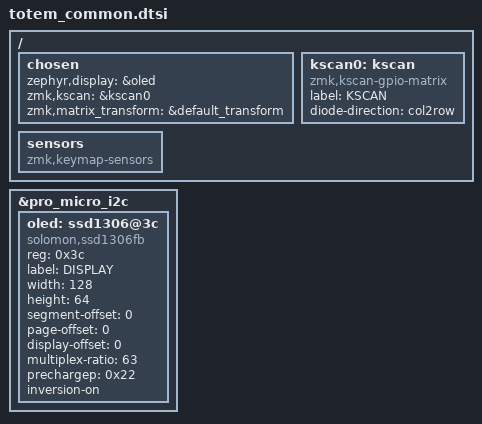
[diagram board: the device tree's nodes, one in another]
/*
 * Copyright (c) 2022 The ZMK Contributors
 *
 * SPDX-License-Identifier: MIT
 */

#include <dt-bindings/zmk/matrix_transform.h>

/ {
	chosen {
		zephyr,display = &oled;
		zmk,kscan = &kscan0;
		zmk,matrix_transform = &default_transform;
	};

	kscan0: kscan {
		compatible = "zmk,kscan-gpio-matrix";
		label = "KSCAN";

		diode-direction = "col2row";		
	};

    sensors: sensors {
        compatible = "zmk,keymap-sensors";
    };

	// TODO: RGB node(s)
};

&pro_micro_i2c {
	status = "okay";

	oled: ssd1306@3c {
		compatible = "solomon,ssd1306fb";
		reg = <0x3c>;
		label = "DISPLAY";
		width = <128>;
		height = <64>;
		segment-offset = <0>;
		page-offset = <0>;
		display-offset = <0>;
		multiplex-ratio = <63>;
		prechargep = <0x22>;
      		inversion-on;
	};
};
